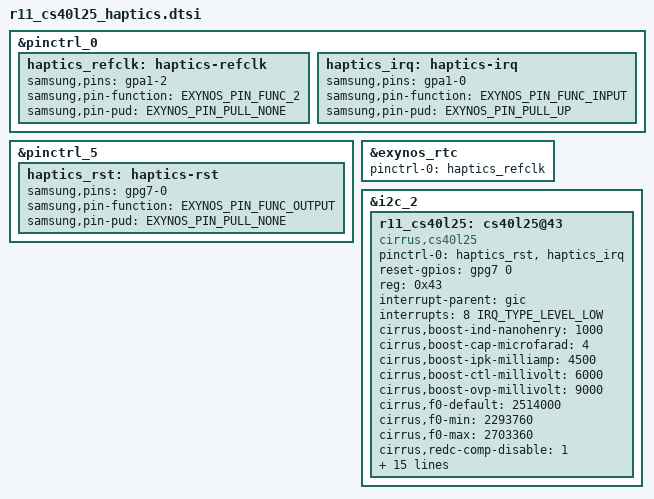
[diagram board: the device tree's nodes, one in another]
/*
 * Device Tree config for the CS40L25 chip - Haptics actuator
 */

#include <dt-bindings/pinctrl/samsung.h>

&pinctrl_0 {
	haptics_refclk: haptics-refclk {
		samsung,pins = "gpa1-2";
		samsung,pin-function = <EXYNOS_PIN_FUNC_2>;
		samsung,pin-pud = <EXYNOS_PIN_PULL_NONE>;
	};

	// Shared with speaker IC
	haptics_irq: haptics-irq {
		// gpio8
		samsung,pins = "gpa1-0";
		samsung,pin-function = <EXYNOS_PIN_FUNC_INPUT>;
		samsung,pin-pud = <EXYNOS_PIN_PULL_UP>;
	};
};

&pinctrl_5 {
	 haptics_rst: haptics-rst {
		// gpio106
		samsung,pins = "gpg7-0";
		samsung,pin-function = <EXYNOS_PIN_FUNC_OUTPUT>;
		samsung,pin-pud = <EXYNOS_PIN_PULL_NONE>;
	};
};

// used to generate 32kHz reference clock for haptics and BT/Wifi devices
&exynos_rtc {
	status = "ok";
	pinctrl-names = "default";
	pinctrl-0 = <&haptics_refclk>;
};

&i2c_2 {
	#address-cells = <1>;
	#size-cells = <0>;
	status = "ok";

	r11_cs40l25: cs40l25@43 {
		compatible = "cirrus,cs40l25";
		pinctrl-names = "default";
		pinctrl-0 = <&haptics_rst &haptics_irq>;
		reset-gpios = <&gpg7 0 GPIO_ACTIVE_HIGH>;
		reg = <0x43>;
		interrupt-parent = <&gic>;
		interrupts = <8 IRQ_TYPE_LEVEL_LOW>;

		cirrus,boost-ind-nanohenry = <1000>;
		cirrus,boost-cap-microfarad = <4>;
		cirrus,boost-ipk-milliamp = <4500>;
		cirrus,boost-ctl-millivolt = <6000>; /* 6V */
		cirrus,boost-ovp-millivolt = <9000>; /* 9V */
		cirrus,f0-default = <2514000>; /* 153 Hz */
		cirrus,f0-min = <2293760>; /* 140 Hz */
		cirrus,f0-max = <2703360>; /* 165 Hz */
		cirrus,redc-comp-disable = <1>; /* disabling ReDC clk comp */
		cirrus,redc-default = <327728>; /* 15 Ohm */
		cirrus,redc-min = <302112>; /* 13.5 Ohm */
		cirrus,redc-max = <369248>; /* 16.5 Ohm */
		cirrus,gpio1-rise-index = <5>; /* 100% HEAVY_CLICK */
		cirrus,gpio1-fall-index = <4>; /* 75% HEAVY_CLICK */
		cirrus,gpio1-fall-timeout = <47278>; /* 985 ms */
		cirrus,gpio1-mode = <2>; /* enabled only in suspend mode */
		cirrus,hiber-enable;
		cirrus,refclk-gpio2;
		cirrus,asp-bclk-freq-hz = <6144000>;
		cirrus,asp-bclk-inv;
		cirrus,asp-fmt = <0>;
		cirrus,asp-slot-num = <2>;
		cirrus,asp-slot-width = <32>;
		cirrus,asp-samp-width = <24>;
		status = "ok";
	};
};
